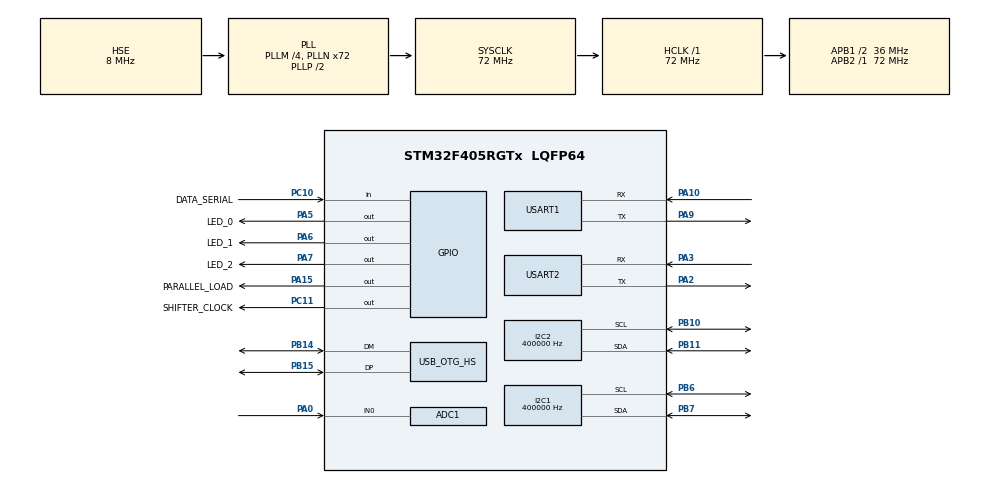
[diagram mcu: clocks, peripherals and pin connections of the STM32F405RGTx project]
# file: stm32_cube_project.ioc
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ADC1.Channel-0\#ChannelRegularConversion=ADC_CHANNEL_0
ADC1.ClockPrescaler=ADC_CLOCK_SYNC_PCLK_DIV8
ADC1.ContinuousConvMode=ENABLE
ADC1.NbrOfConversionFlag=1
ADC1.Rank-0\#ChannelRegularConversion=1
ADC1.SamplingTime-0\#ChannelRegularConversion=ADC_SAMPLETIME_3CYCLES
ADC1.master=1
FREERTOS.INCLUDE_vTaskDelayUntil=1
FREERTOS.Tasks01=defaultTask,0,128,StartDefaultTask,Default,NULL,Dynamic,NULL,NULL
FREERTOS.configMAX_PRIORITIES=4
FREERTOS.configUSE_NEWLIB_REENTRANT=1
I2C1.ClockSpeed=400000
I2C1.DutyCycle=I2C_DUTYCYCLE_16_9
I2C1.I2C_Mode=I2C_Fast
I2C2.ClockSpeed=400000
I2C2.DutyCycle=I2C_DUTYCYCLE_16_9
I2C2.I2C_Mode=I2C_Fast
Mcu.Family=STM32F4
Mcu.Name=STM32F405RGTx
Mcu.Package=LQFP64
NVIC.ADC_IRQn=true\:5\:0\:false\:false\:true\:true\:true\:true\:true
NVIC.I2C1_EV_IRQn=true\:5\:0\:false\:false\:true\:true\:true\:true\:true
NVIC.I2C2_EV_IRQn=true\:5\:0\:false\:false\:true\:true\:true\:true\:true
NVIC.OTG_HS_IRQn=true\:5\:0\:false\:false\:true\:true\:false\:true\:true
NVIC.PriorityGroup=NVIC_PRIORITYGROUP_4
NVIC.TIM1_UP_TIM10_IRQn=true\:15\:0\:false\:false\:true\:false\:false\:true\:true
NVIC.TimeBase=TIM1_UP_TIM10_IRQn
NVIC.TimeBaseIP=TIM1
NVIC.USART2_IRQn=true\:5\:0\:false\:false\:true\:true\:true\:true\:true
PA0-WKUP.Signal=ADCx_IN0
PA10.Mode=Asynchronous
PA10.Signal=USART1_RX
PA13.Signal=SYS_JTMS-SWDIO
PA14.Signal=SYS_JTCK-SWCLK
PA15.GPIO_Label=PARALLEL_LOAD
PA15.Signal=GPIO_Output
PA2.Mode=Asynchronous
PA2.Signal=USART2_TX
PA3.Mode=Asynchronous
PA3.Signal=USART2_RX
PA5.GPIO_Label=LED_0
PA5.Signal=GPIO_Output
PA6.GPIO_Label=LED_1
PA6.Signal=GPIO_Output
PA7.GPIO_Label=LED_2
PA7.Signal=GPIO_Output
PA9.Mode=Asynchronous
PA9.Signal=USART1_TX
PB10.Mode=I2C
PB10.Signal=I2C2_SCL
PB11.Mode=I2C
PB11.Signal=I2C2_SDA
PB14.Mode=Device_Only_FS
PB14.Signal=USB_OTG_HS_DM
PB15.Mode=Device_Only_FS
PB15.Signal=USB_OTG_HS_DP
PB6.Mode=I2C
PB6.Signal=I2C1_SCL
PB7.Mode=I2C
PB7.Signal=I2C1_SDA
PC10.GPIO_Label=DATA_SERIAL
PC10.Signal=GPIO_Input
PC11.GPIO_Label=SHIFTER_CLOCK
PC11.Signal=GPIO_Output
PH0-OSC_IN.Mode=HSE-External-Oscillator
PH0-OSC_IN.Signal=RCC_OSC_IN
PH1-OSC_OUT.Mode=HSE-External-Oscillator
PH1-OSC_OUT.Signal=RCC_OSC_OUT
ProjectManager.HeapSize=0x200
ProjectManager.StackSize=0x400
ProjectManager.TargetToolchain=STM32CubeIDE
RCC.48MHZClocksFreq_Value=48000000
RCC.AHBFreq_Value=72000000
RCC.APB1CLKDivider=RCC_HCLK_DIV2
RCC.APB1Freq_Value=36000000
RCC.APB1TimFreq_Value=72000000
RCC.APB2Freq_Value=72000000
RCC.APB2TimFreq_Value=72000000
RCC.CortexFreq_Value=72000000
RCC.HCLKFreq_Value=72000000
RCC.HSE_VALUE=8000000
RCC.HSI_VALUE=16000000
RCC.LSE_VALUE=32768
RCC.PLLM=4
RCC.PLLN=72
RCC.PLLQ=3
RCC.SYSCLKFreq_VALUE=72000000
RCC.SYSCLKSource=RCC_SYSCLKSOURCE_PLLCLK
RCC.VCOOutputFreq_Value=144000000
SH.ADCx_IN0.0=ADC1_IN0,IN0
USART1.VirtualMode=VM_ASYNC
USART2.VirtualMode=VM_ASYNC
USB_DEVICE.CLASS_NAME_HS=CUSTOM_HID
USB_DEVICE.VirtualMode-CUSTOM_HID_HS=CustomHid
USB_DEVICE.VirtualModeHS=Custom_Hid_HS
USB_OTG_HS.VirtualMode-Device_Only_FS=Device_Only_FS
VP_FREERTOS_VS_CMSIS_V1.Mode=CMSIS_V1
VP_SYS_VS_tim1.Mode=TIM1
VP_USB_DEVICE_VS_USB_DEVICE_CUSTOM_HID_HS.Mode=CUSTOM_HID_HS
board=custom

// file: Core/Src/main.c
/* USER CODE BEGIN Header */
/**
  ******************************************************************************
  * @file           : main.c
  * @brief          : Main program body
  ******************************************************************************
  * @attention
  *
  * Copyright (c) 2024 STMicroelectronics.
  * All rights reserved.
  *
  * This software is licensed under terms that can be found in the LICENSE file
  * in the root directory of this software component.
  * If no LICENSE file comes with this software, it is provided AS-IS.
  *
  ******************************************************************************
  */
/* USER CODE END Header */
#include "main.h"
#include "cmsis_os.h"
#include "usb_device.h"

/* USER CODE BEGIN Includes */
#include "task_led.h"
#include "task_imu.h"
#include "task_uart_output.h"
#include "task_bmi085.h"
/* USER CODE END Includes */

ADC_HandleTypeDef hadc1;

I2C_HandleTypeDef hi2c1;
I2C_HandleTypeDef hi2c2;

UART_HandleTypeDef huart1;
UART_HandleTypeDef huart2;

osThreadId defaultTaskHandle;

void SystemClock_Config(void);
static void MX_GPIO_Init(void);
static void MX_ADC1_Init(void);
static void MX_I2C1_Init(void);
static void MX_I2C2_Init(void);
static void MX_USART2_UART_Init(void);
static void MX_USART1_UART_Init(void);
void StartDefaultTask(void const * argument);

int main(void)
{

  /* MCU Configuration--------------------------------------------------------*/

  /* Reset of all peripherals, Initializes the Flash interface and the Systick. */
  HAL_Init();

  /* Configure the system clock */
  SystemClock_Config();

  /* Initialize all configured peripherals */
  MX_GPIO_Init();
  MX_ADC1_Init();
  MX_I2C1_Init();
  MX_I2C2_Init();
  MX_USART2_UART_Init();
  MX_USART1_UART_Init();

  /* Create the thread(s) */
  /* definition and creation of defaultTask */
  //osThreadDef(defaultTask, StartDefaultTask, osPriorityNormal, 0, 128);
  //defaultTaskHandle = osThreadCreate(osThread(defaultTask), NULL);

  /* USER CODE BEGIN RTOS_THREADS */
  /* add threads, ... */
  //task_imu_init();
  task_led_init();
  task_bmi085_init();
  task_uart_output_init();
  /* USER CODE END RTOS_THREADS */

  /* Start scheduler */
  osKernelStart();

  /* We should never get here as control is now taken by the scheduler */

  /* Infinite loop */
  while (1)
  {

  }
}

void SystemClock_Config(void)
{
  RCC_OscInitTypeDef RCC_OscInitStruct = {0};
  RCC_ClkInitTypeDef RCC_ClkInitStruct = {0};

  /** Configure the main internal regulator output voltage
  */
  __HAL_RCC_PWR_CLK_ENABLE();
  __HAL_PWR_VOLTAGESCALING_CONFIG(PWR_REGULATOR_VOLTAGE_SCALE1);

  /** Initializes the RCC Oscillators according to the specified parameters
  * in the RCC_OscInitTypeDef structure.
  */
  RCC_OscInitStruct.OscillatorType = RCC_OSCILLATORTYPE_HSE;
  RCC_OscInitStruct.HSEState = RCC_HSE_ON;
  RCC_OscInitStruct.PLL.PLLState = RCC_PLL_ON;
  RCC_OscInitStruct.PLL.PLLSource = RCC_PLLSOURCE_HSE;
  RCC_OscInitStruct.PLL.PLLM = 4;
  RCC_OscInitStruct.PLL.PLLN = 72;
  RCC_OscInitStruct.PLL.PLLP = RCC_PLLP_DIV2;
  RCC_OscInitStruct.PLL.PLLQ = 3;
  if (HAL_RCC_OscConfig(&RCC_OscInitStruct) != HAL_OK)
  {
    Error_Handler();
  }

  /** Initializes the CPU, AHB and APB buses clocks
  */
  RCC_ClkInitStruct.ClockType = RCC_CLOCKTYPE_HCLK|RCC_CLOCKTYPE_SYSCLK
                              |RCC_CLOCKTYPE_PCLK1|RCC_CLOCKTYPE_PCLK2;
  RCC_ClkInitStruct.SYSCLKSource = RCC_SYSCLKSOURCE_PLLCLK;
  RCC_ClkInitStruct.AHBCLKDivider = RCC_SYSCLK_DIV1;
  RCC_ClkInitStruct.APB1CLKDivider = RCC_HCLK_DIV2;
  RCC_ClkInitStruct.APB2CLKDivider = RCC_HCLK_DIV1;

  if (HAL_RCC_ClockConfig(&RCC_ClkInitStruct, FLASH_LATENCY_2) != HAL_OK)
  {
    Error_Handler();
  }
}

static void MX_ADC1_Init(void)
{

  ADC_ChannelConfTypeDef sConfig = {0};

  /** Configure the global features of the ADC (Clock, Resolution, Data Alignment and number of conversion)
  */
  hadc1.Instance = ADC1;
  hadc1.Init.ClockPrescaler = ADC_CLOCK_SYNC_PCLK_DIV8;
  hadc1.Init.Resolution = ADC_RESOLUTION_12B;
  hadc1.Init.ScanConvMode = DISABLE;
  hadc1.Init.ContinuousConvMode = ENABLE;
  hadc1.Init.DiscontinuousConvMode = DISABLE;
  hadc1.Init.ExternalTrigConvEdge = ADC_EXTERNALTRIGCONVEDGE_NONE;
  hadc1.Init.ExternalTrigConv = ADC_SOFTWARE_START;
  hadc1.Init.DataAlign = ADC_DATAALIGN_RIGHT;
  hadc1.Init.NbrOfConversion = 1;
  hadc1.Init.DMAContinuousRequests = DISABLE;
  hadc1.Init.EOCSelection = ADC_EOC_SINGLE_CONV;
  if (HAL_ADC_Init(&hadc1) != HAL_OK)
  {
    Error_Handler();
  }

  /** Configure for the selected ADC regular channel its corresponding rank in the sequencer and its sample time.
  */
  sConfig.Channel = ADC_CHANNEL_0;
  sConfig.Rank = 1;
  sConfig.SamplingTime = ADC_SAMPLETIME_3CYCLES;
  if (HAL_ADC_ConfigChannel(&hadc1, &sConfig) != HAL_OK)
  {
    Error_Handler();
  }

}

static void MX_I2C1_Init(void)
{

  hi2c1.Instance = I2C1;
  hi2c1.Init.ClockSpeed = 400000;
  hi2c1.Init.DutyCycle = I2C_DUTYCYCLE_16_9;
  hi2c1.Init.OwnAddress1 = 0;
  hi2c1.Init.AddressingMode = I2C_ADDRESSINGMODE_7BIT;
  hi2c1.Init.DualAddressMode = I2C_DUALADDRESS_DISABLE;
  hi2c1.Init.OwnAddress2 = 0;
  hi2c1.Init.GeneralCallMode = I2C_GENERALCALL_DISABLE;
  hi2c1.Init.NoStretchMode = I2C_NOSTRETCH_DISABLE;
  if (HAL_I2C_Init(&hi2c1) != HAL_OK)
  {
    Error_Handler();
  }

}

static void MX_I2C2_Init(void)
{

  hi2c2.Instance = I2C2;
  hi2c2.Init.ClockSpeed = 400000;
  hi2c2.Init.DutyCycle = I2C_DUTYCYCLE_16_9;
  hi2c2.Init.OwnAddress1 = 0;
  hi2c2.Init.AddressingMode = I2C_ADDRESSINGMODE_7BIT;
  hi2c2.Init.DualAddressMode = I2C_DUALADDRESS_DISABLE;
  hi2c2.Init.OwnAddress2 = 0;
  hi2c2.Init.GeneralCallMode = I2C_GENERALCALL_DISABLE;
  hi2c2.Init.NoStretchMode = I2C_NOSTRETCH_DISABLE;
  if (HAL_I2C_Init(&hi2c2) != HAL_OK)
  {
    Error_Handler();
  }

}

static void MX_USART1_UART_Init(void)
{

  huart1.Instance = USART1;
  huart1.Init.BaudRate = 115200;
  huart1.Init.WordLength = UART_WORDLENGTH_8B;
  huart1.Init.StopBits = UART_STOPBITS_1;
  huart1.Init.Parity = UART_PARITY_NONE;
  huart1.Init.Mode = UART_MODE_TX_RX;
  huart1.Init.HwFlowCtl = UART_HWCONTROL_NONE;
  huart1.Init.OverSampling = UART_OVERSAMPLING_16;
  if (HAL_UART_Init(&huart1) != HAL_OK)
  {
    Error_Handler();
  }

}

static void MX_USART2_UART_Init(void)
{

  huart2.Instance = USART2;
  huart2.Init.BaudRate = 115200;
  huart2.Init.WordLength = UART_WORDLENGTH_8B;
  huart2.Init.StopBits = UART_STOPBITS_1;
  huart2.Init.Parity = UART_PARITY_NONE;
  huart2.Init.Mode = UART_MODE_TX_RX;
  huart2.Init.HwFlowCtl = UART_HWCONTROL_NONE;
  huart2.Init.OverSampling = UART_OVERSAMPLING_16;
  if (HAL_UART_Init(&huart2) != HAL_OK)
  {
    Error_Handler();
  }

}

static void MX_GPIO_Init(void)
{
  GPIO_InitTypeDef GPIO_InitStruct = {0};

  /* GPIO Ports Clock Enable */
  __HAL_RCC_GPIOH_CLK_ENABLE();
  __HAL_RCC_GPIOA_CLK_ENABLE();
  __HAL_RCC_GPIOB_CLK_ENABLE();
  __HAL_RCC_GPIOC_CLK_ENABLE();

  /*Configure GPIO pin Output Level */
  HAL_GPIO_WritePin(GPIOA, LED_0_Pin|LED_1_Pin|LED_2_Pin|PARALLEL_LOAD_Pin, GPIO_PIN_RESET);

  /*Configure GPIO pin Output Level */
  HAL_GPIO_WritePin(SHIFTER_CLOCK_GPIO_Port, SHIFTER_CLOCK_Pin, GPIO_PIN_RESET);

  /*Configure GPIO pins : LED_0_Pin LED_1_Pin LED_2_Pin PARALLEL_LOAD_Pin */
  GPIO_InitStruct.Pin = LED_0_Pin|LED_1_Pin|LED_2_Pin|PARALLEL_LOAD_Pin;
  GPIO_InitStruct.Mode = GPIO_MODE_OUTPUT_PP;
  GPIO_InitStruct.Pull = GPIO_NOPULL;
  GPIO_InitStruct.Speed = GPIO_SPEED_FREQ_LOW;
  HAL_GPIO_Init(GPIOA, &GPIO_InitStruct);

  /*Configure GPIO pin : DATA_SERIAL_Pin */
  GPIO_InitStruct.Pin = DATA_SERIAL_Pin;
  GPIO_InitStruct.Mode = GPIO_MODE_INPUT;
  GPIO_InitStruct.Pull = GPIO_NOPULL;
  HAL_GPIO_Init(DATA_SERIAL_GPIO_Port, &GPIO_InitStruct);

  /*Configure GPIO pin : SHIFTER_CLOCK_Pin */
  GPIO_InitStruct.Pin = SHIFTER_CLOCK_Pin;
  GPIO_InitStruct.Mode = GPIO_MODE_OUTPUT_PP;
  GPIO_InitStruct.Pull = GPIO_NOPULL;
  GPIO_InitStruct.Speed = GPIO_SPEED_FREQ_LOW;
  HAL_GPIO_Init(SHIFTER_CLOCK_GPIO_Port, &GPIO_InitStruct);

}

void StartDefaultTask(void const * argument)
{
  /* init code for USB_DEVICE */
  MX_USB_DEVICE_Init();
  /* USER CODE BEGIN 5 */
  /* Infinite loop */
  for(;;)
  {
	  HAL_GPIO_TogglePin( LED_0_GPIO_Port, LED_0_Pin );
	  HAL_GPIO_TogglePin( LED_1_GPIO_Port, LED_1_Pin );
	  HAL_GPIO_TogglePin( LED_2_GPIO_Port, LED_2_Pin );
	  osDelay(500);
  }
  /* USER CODE END 5 */
}

void HAL_TIM_PeriodElapsedCallback(TIM_HandleTypeDef *htim)
{
  if (htim->Instance == TIM1) {
    HAL_IncTick();
  }
}

void Error_Handler(void)
{
  __disable_irq();
  while (1)
  {
  }
}
